# SN32F240B register map
Vendor: SONiX Technology Co., Ltd.; Series: SN32F240B; File version: 1.0
CPU: CM0 r0p0, little endian, no MPU, no FPU, 2 interrupt priority bits
Registers are 32-bit, read-write, reset 0x0 unless marked. A register's access mark holds for its fields unless they carry their own. Offsets are from the block's base; [hi:lo] are bit positions; {n}, {i} and the like mark numbered series; 'fields as' and 'values as' point back to an identical list.

## SN_CT16B1 — 16-bit Timer 0 with Capture function
Base 0x40002000
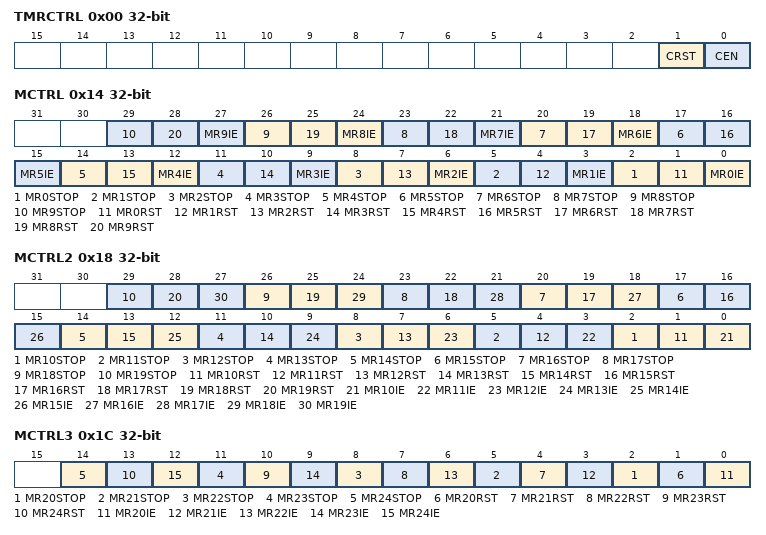
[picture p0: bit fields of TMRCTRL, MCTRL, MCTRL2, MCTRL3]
0x00 TMRCTRL — Offset:0x00 CT16Bn Timer Control Register
  [1] CRST — Counter Reset
    0=Disable; 1=Reset Counter (Timer Counter and the Prescale Counter are synchronously reset on the next positive edge of PCLK)
  [0] CEN — Counter enable
    0=Disable counter; 1=Enable Timer Counter and Prescale Counter for counting
0x04 TC — Offset:0x04 CT16Bn Timer Counter Register
  [15:0] TC — Timer Counter
0x08 PRE — Offset:0x08 CT16Bn Prescale Register
  [7:0] PRE — Prescaler
0x0C PC — Offset:0x0C CT16Bn Prescale Counter Register
  [7:0] PC — Prescaler Counter
0x14 MCTRL (reset mask 0x3FFFFFF) — Offset:0x14 CT16Bn Match Control Register
  [3n+2] MR{n}STOP (n=0..9) — Stop TC and PC and clear CEN bit when MR{n} matches TC
    0=Disable; 1=Enable (Stop TC and PC and clear CEN bit when MR{n} matches TC)
  [3n+1] MR{n}RST (n=0..9) — Enable reset TC when MR{n} matches TC
    0=Disable; 1=Enable (Reset TC when MR{n} matches TC)
  [3n] MR{n}IE (n=0..9) — Enable generating an interrupt when MR{n} matches TC
    0=Disable; 1=Enable (Generating an interrupt when MR{n} matches TC)
0x18 MCTRL2 (reset mask 0x3FFFFFF) — Offset:0x18 CT16Bn Match Control Register 2
  [3n-28] MR{n}STOP (n=10..19) — Stop TC and PC and clear CEN bit when MR{n} matches TC
    values as MCTRL.MR0STOP
  [3n-29] MR{n}RST (n=10..19) — Enable reset TC when MR{n} matches TC
    0=Disable; 1=Enable (Reset TC when MR{n} matches TC)
  [3n-30] MR{n}IE (n=10..19) — Enable generating an interrupt when MR{n} matches TC
    values as MCTRL.MR0IE
0x1C MCTRL3 — Offset:0x1C CT16Bn Match Control Register 3
  [3n-58] MR{n}STOP (n=20..24) — Stop TC and PC and clear CEN bit when MR{n} matches TC
    values as MCTRL.MR0STOP
  [3n-59] MR{n}RST (n=20..24) — Enable reset TC when MR{n} matches TC
    0=Disable; 1=Enable (Reset TC when MR{n} matches TC)
  [3n-60] MR{n}IE (n=20..24) — Enable generating an interrupt when MR{n} matches TC
    values as MCTRL.MR0IE
{0x20+4i} MR{i} (reset mask 0xFFFF) (i=0..24) — Offset:{0x20+4i} CT16Bn MR{i} Register
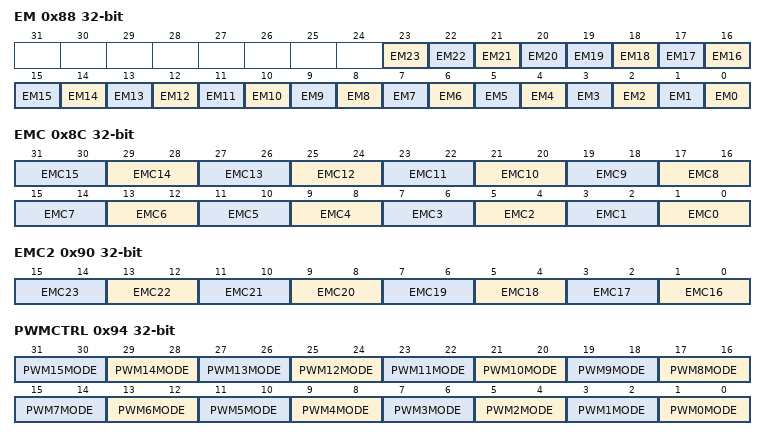
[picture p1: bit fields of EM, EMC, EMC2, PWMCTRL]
0x88 EM — Offset:0x88 CT16Bn External Match Register
  [23] EM23 — When the TC matches MR23, this bit will act according to EMC23[1:0], and also drive the state of CT16Bn_PWM2 output.
  [22] EM22 — When the TC matches MR22, this bit will act according to EMC22[1:0], and also drive the state of CT16Bn_PWM2 output.
  [21] EM21 — When the TC matches MR21, this bit will act according to EMC21[1:0], and also drive the state of CT16Bn_PWM1 output.
  [20] EM20 — When the TC matches MR20, this bit will act according to EMC20[1:0], and also drive the state of CT16Bn_PWM0 output.
  [n] EM{n} (n=16..19) — When the TC matches MR{n}, this bit will act according to EMC{n}[1:0], and also drive the state of CT16Bn_PWM{n-16} output.
  [n] EM{n} (n=12..15) — When the TC matches MR{n}, this bit will act according to EMC{n}[1:0], and also drive the state of CT16Bn_PWM{n-12} output.
  [n] EM{n} (n=8..11) — When the TC matches MR{n}, this bit will act according to EMC{n}[1:0], and also drive the state of CT16Bn_PWM{n-8} output.
  [n] EM{n} (n=4..7) — When the TC matches MR{n}, this bit will act according to EMC{n}[1:0], and also drive the state of CT16Bn_PWM{n-4} output.
  [n] EM{n} (n=0..3) — When the TC matches MR{n}, this bit will act according to EMC{n}[1:0], and also drive the state of CT16Bn_PWM{n} output.
0x8C EMC — Offset:0x8C CT16Bn External Match Control register
  [2n+1:2n] EMC{n} (n=0..15) — CT16Bn_PWM{n} functionality
    0=Do Nothing; 1=Low (CT16Bn_PWM{n} pin is LOW); 2=High (CT16Bn_PWM{n} pin is HIGH); 3=Toggle CT16Bn_PWM{n} pin
0x90 EMC2 — Offset:0x90 CT16Bn External Match Control register 2
  [2n-31:2n-32] EMC{n} (n=16..23) — CT16Bn_PWM{n} functionality
    values as EMC.EMC0
0x94 PWMCTRL — Offset:0x94 CT16Bn PWM Control Register
  [2n+1:2n] PWM{n}MODE (n=0..15) — PWM{n} output mode
    0=PWM mode 1 (During up-counting, PWM{n} is 0 when TC is less than MR{n}. During down-counting, PWM{n} is 1 when TC is larger/equal than MR{n}); 1=PWM mode 2 (During up-counting, PWM{n} is 1 when TC is less than MR{n}. During down-counting, PWM{n} is 0 when TC is larger/equal than MR{n}); 2=Force 0 (PWM{n} is forced to 0); 3=Force 1 (PWM{n} is forced to 1)
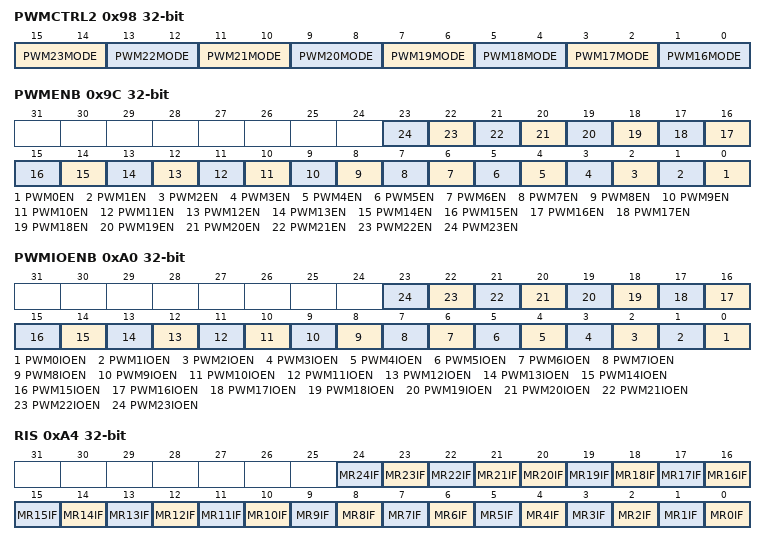
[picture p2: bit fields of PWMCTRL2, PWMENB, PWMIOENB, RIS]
0x98 PWMCTRL2 — Offset:0x98 CT16Bn PWM Control Register 2
  [15:14] PWM23MODE — PWM23 output mode
    0=PWM mode 1 (During up-counting, PWM23 is 0 when TC is less than MR23. During down-counting, PWM22 is 1 when TC is larger/equal than MR23); 1=PWM mode 2 (During up-counting, PWM23 is 1 when TC is less than MR23. During down-counting, PWM22 is 0 when TC is larger/equal than MR23); 2=Force 0 (PWM23 is forced to 0); 3=Force 1 (PWM23 is forced to 1)
  [2n-31:2n-32] PWM{n}MODE (n=16..22) — PWM{n} output mode
    values as PWMCTRL.PWM0MODE
0x9C PWMENB — Offset:0x9C CT16Bn PWM Enable register
  [n] PWM{n}EN (n=0..23) — PWM{n} enable
    0=Disable (CT16Bn_PWM{n} is controlled by EM{n}); 1=Enable PWM mode for CT16Bn_PWM{n}
0xA0 PWMIOENB — Offset:0xA0 CT16Bn PWM IO Enable register
  [n] PWM{n}IOEN (n=0..23) — CT16Bn_PWM{n}/GPIO selection
    0=Disable (CT16Bn_PWM{n} pin is act as GPIO); 1=Enable (CT16Bn_PWM{n} pin act as match output, and output depends on PWM{n}EN bit)
0xA4 RIS ro — Offset:0xA4 CT16Bn Raw Interrupt Status Register
  [n] MR{n}IF (n=21..24) — Match channel {n} interrupt flag
    0=No (No interrupt on match channel {n}); 1=Met interrupt requirements (Interrupt requirements met on match channel {n})
  [20] MR20IF — Match channel 20 interrupt flag
    0=No interrupt on match channel 20; 1=Met interrupt requirements (Interrupt requirements met on match channel 20)
  [19] MR19IF — Match channel 19 interrupt flag
    0=No (No interrupt on match channel 19); 1=Met interrupt requirements (Interrupt requirements met on match channel 19)
  [18] MR18IF — Match channel 18 interrupt flag
    0=No (No interrupt on match channel 18); 1=Met interrupt requirements (Interrupt requirements met on match channel 18)
  [17] MR17IF — Match channel 17 interrupt flag
    0=No (No interrupt on match channel 17); 1=Met interrupt requirements (Interrupt requirements met on match channel 17)
  [16] MR16IF — Match channel 16 interrupt flag
    0=No interrupt on match channel 16; 1=Met interrupt requirements (Interrupt requirements met on match channel 16)
  [15] MR15IF — Match channel 15 interrupt flag
    0=No (No interrupt on match channel 15); 1=Met interrupt requirements (Interrupt requirements met on match channel 15)
  [14] MR14IF — Match channel 14 interrupt flag
    0=No (No interrupt on match channel 14); 1=Met interrupt requirements (Interrupt requirements met on match channel 14)
  [13] MR13IF — Match channel 13 interrupt flag
    0=No (No interrupt on match channel 13); 1=Met interrupt requirements (Interrupt requirements met on match channel 13)
  [12] MR12IF — Match channel 12 interrupt flag
    0=No interrupt on match channel 12; 1=Met interrupt requirements (Interrupt requirements met on match channel 12)
  [11] MR11IF — Match channel 11 interrupt flag
    0=No (No interrupt on match channel 11); 1=Met interrupt requirements (Interrupt requirements met on match channel 11)
  [10] MR10IF — Match channel 10 interrupt flag
    0=No (No interrupt on match channel 10); 1=Met interrupt requirements (Interrupt requirements met on match channel 10)
  [9] MR9IF — Match channel 9 interrupt flag
    0=No (No interrupt on match channel 9); 1=Met interrupt requirements (Interrupt requirements met on match channel 9)
  [8] MR8IF — Match channel 8 interrupt flag
    0=No interrupt on match channel 8; 1=Met interrupt requirements (Interrupt requirements met on match channel 8)
  [7] MR7IF — Match channel 7 interrupt flag
    0=No (No interrupt on match channel 7); 1=Met interrupt requirements (Interrupt requirements met on match channel 7)
  [6] MR6IF — Match channel 6 interrupt flag
    0=No (No interrupt on match channel 6); 1=Met interrupt requirements (Interrupt requirements met on match channel 6)
  [5] MR5IF — Match channel 5 interrupt flag
    0=No (No interrupt on match channel 5); 1=Met interrupt requirements (Interrupt requirements met on match channel 5)
  [4] MR4IF — Match channel 4 interrupt flag
    0=No interrupt on match channel 4; 1=Met interrupt requirements (Interrupt requirements met on match channel 4)
  [3] MR3IF — Match channel 3 interrupt flag
    0=No (No interrupt on match channel 3); 1=Met interrupt requirements (Interrupt requirements met on match channel 3)
  [2] MR2IF — Match channel 2 interrupt flag
    0=No (No interrupt on match channel 2); 1=Met interrupt requirements (Interrupt requirements met on match channel 2)
  [1] MR1IF — Match channel 1 interrupt flag
    0=No (No interrupt on match channel 1); 1=Met interrupt requirements (Interrupt requirements met on match channel 1)
  [0] MR0IF — Match channel 0 interrupt flag
    0=No interrupt on match channel 0; 1=Met interrupt requirements (Interrupt requirements met on match channel 0)
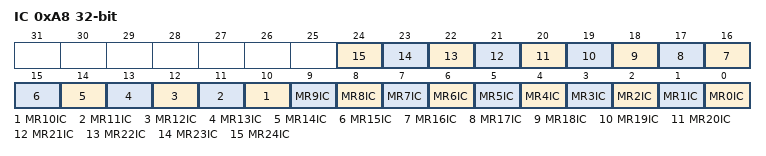
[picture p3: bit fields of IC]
0xA8 IC wo — Offset:0xA8 CT16Bn Interrupt Clear Register
  [n] MR{n}IC (n=0..24) — MR{n}IF clear bit
    0=No effect; 1=Clear MR{n}IF

## Notices in the file
Copyright (C) 2017 ARM Limited. All rights reserved.
